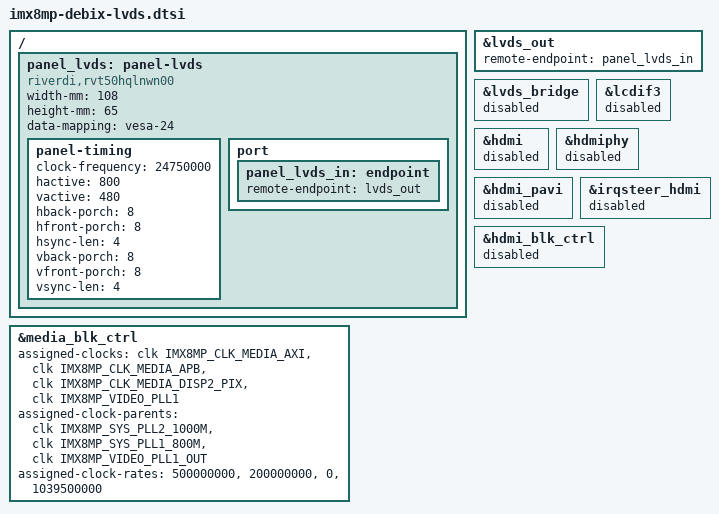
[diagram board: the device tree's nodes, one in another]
// SPDX-License-Identifier: (GPL-2.0+ OR MIT)
/*
 * imx8mp-debix-lvds.dtsi — DEBIX の表示を J10 の LVDS パネルにする (既定、DEBIX_DISPLAY = "lvds")。
 * imx8mp-debix.dts が include する (カーネルのレシピがこのファイルを選ぶ)。
 *
 * J10 の LVDS0 → 変換基板 (debix-hat/lvds-adapter) → Riverdi RVT50HQLNWN00 (800x480)。
 * 経路は lcdif2 → LDB ch0 → LVDS PHY → panel-lvds。HDMI (lcdif3 + DW-HDMI 一式) は止める。
 */

/* ===== 表示: LVDS パネル (J10 の LVDS0) =====
 * lcdif2 → LDB の ch0 → LVDS PHY → panel-lvds。ldb/ldb_phy/lcdif2/lvds-channel@0 は
 * EVK の dts が okay にしているので、ここでは出口の先を IT6263 からパネルに付け替える。
 * DT とカーネルの cfg は必ずセット (slim-imx8mp.cfg の DRM_IMX8MP_LDB・DRM_PANEL_LVDS):
 * ノードが有効でドライバが無いと imx-drm のコンポーネント束ねが ldb を待ち続け、
 * display-subsystem (= /dev/dri の表示カード) ごと現れず weston が「no drm device found」
 * で死ぬ (2026-09-02 実測)。
 */
/ {
	/*
	 * Riverdi RVT50HQLNWN00: 5 インチ 800x480、VESA 24 ビット (変換基板で SELB を High、
	 * L/R・U/D も High = 反転なし)。タイミングはデータシート (DS_RVT50HQLNWN00 Rev.1.0)
	 * の標準値。クロックだけ 25 MHz ではなく 24.75 MHz (= video_pll1 1039.5 MHz / 42):
	 * LDB はピクセルクロックのちょうど 7 倍 (173.25 MHz = / 6) が要り、25 MHz だと同じ
	 * PLL から 7 倍の比で割れない。パネルの範囲は 23〜27 MHz で、更新は約 60.4 Hz。
	 * NXP の LDB のドライバは 1 チャネルのときクロックを 74.25 MHz に書き換えるので、
	 * パッチ 0014 でパネルのときは書き換えないようにしている (無いと約 3 倍のクロックで
	 * 真っ黒になる。2026-11-10 実測)。
	 *
	 * 電源とバックライトは変換基板が J10 の 5 V から作る (3.3 V の LDO と LED の定電流)。
	 * 5 V は J10 の負荷スイッチの EN (回路図の LVDS_PWR_EN = GPIO4_IO25) で入り、
	 * GPIO4_IO25 は imx8mp-debix.dts の usb-rst-hog が起動時から High に保つので
 * power-supply は書かない。
	 * RESET/STBYB は変換基板の RC で順番に上がり、バックライトの制御線も J10 に無い。
	 */
	panel_lvds: panel-lvds {
		compatible = "riverdi,rvt50hqlnwn00", "panel-lvds";
		width-mm = <108>;
		height-mm = <65>;
		data-mapping = "vesa-24";

		panel-timing {
			clock-frequency = <24750000>;
			hactive = <800>;
			vactive = <480>;
			hback-porch = <8>;
			hfront-porch = <8>;
			hsync-len = <4>;
			vback-porch = <8>;
			vfront-porch = <8>;
			vsync-len = <4>;
		};

		port {
			panel_lvds_in: endpoint {
				remote-endpoint = <&lvds_out>;
			};
		};
	};
};

&lvds_out {
	remote-endpoint = <&panel_lvds_in>;
};

/* EVK の LVDS→HDMI ブリッジ (IT6263)。DEBIX に無い (ドライバも slim で外してある) */
&lvds_bridge {
	status = "disabled";
};

/* HDMI は使わない。lcdif3 と DW-HDMI・PHY・PVI、HDMI の割り込みと電源の区画
 * (hdmi_blk_ctrl) を止める。hdmi_blk_ctrl の電源の区画と irqsteer_hdmi を使うのは
 * ここで止める HDMI のノードだけ (imx8mp.dtsi)。 */
&lcdif3 {
	status = "disabled";
};

&hdmi {
	status = "disabled";
};

&hdmiphy {
	status = "disabled";
};

&hdmi_pavi {
	status = "disabled";
};

&irqsteer_hdmi {
	status = "disabled";
};

&hdmi_blk_ctrl {
	status = "disabled";
};

/* media blk-ctrl のクロックの初期設定から DISP1_PIX (lcdif1 = MIPI DSI のピクセル。
 * DEBIX では lcdif1・DSI とも止めてある) を外す。SPL は disp1 に触らない (リセット値の
 * osc_24m のまま) ので、EVK の設定のままだとカーネルが blk-ctrl の probe の直前に disp1 の
 * 親を video_pll1_out に付け替える。ルートクロックは CLK_OPS_PARENT_ENABLE 付きで、
 * 付け替えの間だけ新しい親を有効にして戻すため、まだ誰も video_pll1_out を握っていない
 * この時点では PLL の出力 (GEN_CTRL の CLKE) が実際に落ちる。SPL のスプラッシュを出した
 * まま引き継いでいると、ピクセルクロックと LDB のシリアルクロックが止まり、パネルの表示が
 * 1〜2 フレーム崩れた (2026-11-11 実測)。残りは EVK と同じ */
&media_blk_ctrl {
	assigned-clocks = <&clk IMX8MP_CLK_MEDIA_AXI>,
			  <&clk IMX8MP_CLK_MEDIA_APB>,
			  <&clk IMX8MP_CLK_MEDIA_DISP2_PIX>,
			  <&clk IMX8MP_VIDEO_PLL1>;
	assigned-clock-parents = <&clk IMX8MP_SYS_PLL2_1000M>,
				 <&clk IMX8MP_SYS_PLL1_800M>,
				 <&clk IMX8MP_VIDEO_PLL1_OUT>;
	assigned-clock-rates = <500000000>, <200000000>,
			       <0>, <1039500000>;
};
